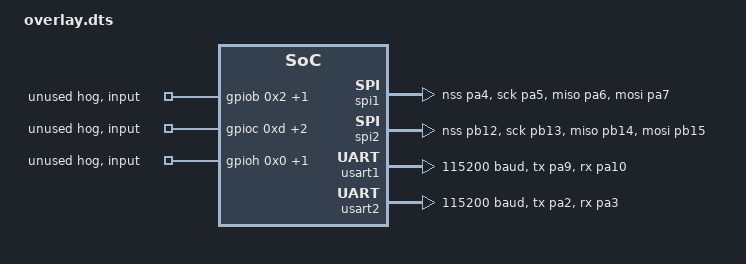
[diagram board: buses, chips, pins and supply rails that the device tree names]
/ {
	compatible = "google,dragonclaw-fpmcu";
	chosen {
		zephyr,console = &usart2;
		zephyr,sram = &sram0;
		zephyr,flash = &flash0;
	};
};
&clk_hsi{
	status = "okay";
};
&spi1{
	status = "okay";
	pinctrl-0 = < &spi1_nss_pa4 &spi1_sck_pa5 &spi1_miso_pa6 &spi1_mosi_pa7 >;
	pinctrl-names = "default";
};
&pll{
	status = "okay";
	div-m = < 0x8 >;
	mul-n = < 0xc0 >;
	div-p = < 0x4 >;
	div-q = < 0x8 >;
	div-r = < 0x7 >;
	clocks = < &clk_hsi >;
};
&clk_lsi{
	status = "okay";
};
&rcc{
	clocks = < &pll >;
	clock-frequency = < 0x5b8d800 >;
	apb1-prescaler = < 0x2 >;
	apb2-prescaler = < 0x2 >;
};
&spi2{
	status = "okay";
	pinctrl-0 = < &spi2_nss_pb12 &spi2_sck_pb13 &spi2_miso_pb14 &spi2_mosi_pb15 >;
	pinctrl-names = "default";
};
&usart1{
	status = "okay";
	pinctrl-0 = < &usart1_tx_pa9 &usart1_rx_pa10 >;
	pinctrl-names = "default";
	current-speed = < 0x1c200 >;
};
&usart2{
	status = "okay";
	pinctrl-0 = < &usart2_tx_pa2 &usart2_rx_pa3 >;
	pinctrl-names = "default";
	current-speed = < 0x1c200 >;
};
&pinctrl{
	compatible = "st,stm32-pinctrl";
	#address-cells = < 0x1 >;
	#size-cells = < 0x1 >;
	reg = < 0x40020000 0x1c00 >;
	gpioa: gpio@40020000 {
		compatible = "st,stm32-gpio";
		gpio-controller;
		#gpio-cells = < 0x2 >;
		reg = < 0x40020000 0x400 >;
		clocks = < &rcc 0x30 0x1 >;
	};
	gpiob: gpio@40020400 {
		compatible = "st,stm32-gpio";
		gpio-controller;
		#gpio-cells = < 0x2 >;
		reg = < 0x40020400 0x400 >;
		clocks = < &rcc 0x30 0x2 >;
		unused {
			gpio-hog;
			gpios = < 0x2 0x0 >, < 0x5 0x0 >;
		};
	};
	gpioc: gpio@40020800 {
		compatible = "st,stm32-gpio";
		gpio-controller;
		#gpio-cells = < 0x2 >;
		reg = < 0x40020800 0x400 >;
		clocks = < &rcc 0x30 0x4 >;
		unused {
			gpio-hog;
			gpios = < 0xd 0x0 >, < 0xe 0x0 >, < 0xf 0x0 >;
		};
	};
	gpiod: gpio@40020c00 {
		compatible = "st,stm32-gpio";
		gpio-controller;
		#gpio-cells = < 0x2 >;
		reg = < 0x40020c00 0x400 >;
		clocks = < &rcc 0x30 0x8 >;
		status = "disabled";
	};
	gpioe: gpio@40021000 {
		compatible = "st,stm32-gpio";
		gpio-controller;
		#gpio-cells = < 0x2 >;
		reg = < 0x40021000 0x400 >;
		clocks = < &rcc 0x30 0x10 >;
		status = "disabled";
	};
	gpiof: gpio@40021400 {
		compatible = "st,stm32-gpio";
		gpio-controller;
		#gpio-cells = < 0x2 >;
		reg = < 0x40021400 0x400 >;
		clocks = < &rcc 0x30 0x20 >;
		status = "disabled";
	};
	gpiog: gpio@40021800 {
		compatible = "st,stm32-gpio";
		gpio-controller;
		#gpio-cells = < 0x2 >;
		reg = < 0x40021800 0x400 >;
		clocks = < &rcc 0x30 0x40 >;
		status = "disabled";
	};
	gpioh: gpio@40021c00 {
		compatible = "st,stm32-gpio";
		gpio-controller;
		#gpio-cells = < 0x2 >;
		reg = < 0x40021c00 0x400 >;
		clocks = < &rcc 0x30 0x80 >;
		unused {
			gpio-hog;
			gpios = < 0x0 0x0 >, < 0x1 0x0 >;
		};
	};
	spi1_miso_pa6: spi1_miso_pa6 {
		pinmux = < 0xc5 >;
		bias-pull-down;
	};
	spi2_miso_pb14: spi2_miso_pb14 {
		pinmux = < 0x3c5 >;
		bias-pull-down;
	};
	spi1_mosi_pa7: spi1_mosi_pa7 {
		pinmux = < 0xe5 >;
		bias-pull-down;
	};
	spi2_mosi_pb15: spi2_mosi_pb15 {
		pinmux = < 0x3e5 >;
		bias-pull-down;
	};
	spi1_nss_pa4: spi1_nss_pa4 {
		pinmux = < 0x85 >;
		bias-pull-up;
	};
	spi2_nss_pb12: spi2_nss_pb12 {
		pinmux = < 0x385 >;
		bias-pull-up;
	};
	spi1_sck_pa5: spi1_sck_pa5 {
		pinmux = < 0xa5 >;
		bias-pull-down;
		slew-rate = "very-high-speed";
	};
	spi2_sck_pb13: spi2_sck_pb13 {
		pinmux = < 0x3a5 >;
		bias-pull-down;
		slew-rate = "very-high-speed";
	};
	usart1_rx_pa10: usart1_rx_pa10 {
		pinmux = < 0x147 >;
	};
	usart2_rx_pa3: usart2_rx_pa3 {
		pinmux = < 0x67 >;
	};
	usart1_tx_pa9: usart1_tx_pa9 {
		pinmux = < 0x127 >;
		bias-pull-up;
	};
	usart2_tx_pa2: usart2_tx_pa2 {
		pinmux = < 0x47 >;
		bias-pull-up;
	};
};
